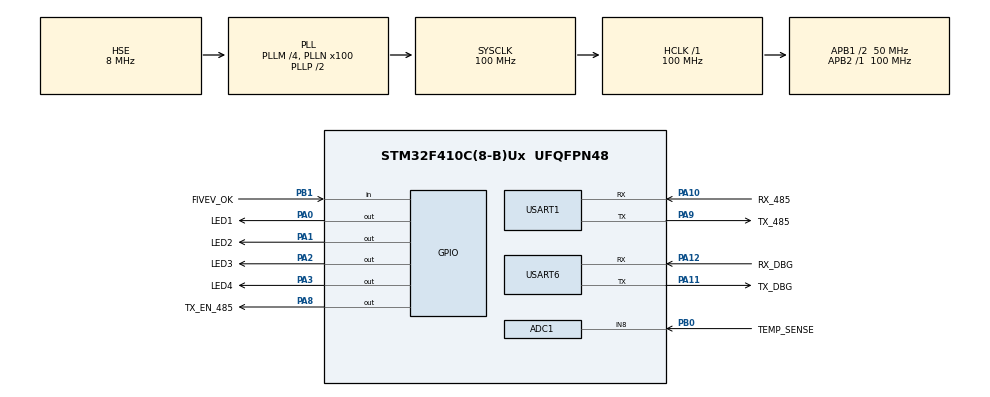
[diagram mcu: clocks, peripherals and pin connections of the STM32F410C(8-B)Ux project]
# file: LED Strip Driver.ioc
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ADC1.Channel-8\#ChannelRegularConversion=ADC_CHANNEL_8
ADC1.NbrOfConversionFlag=1
ADC1.Rank-8\#ChannelRegularConversion=1
ADC1.SamplingTime-8\#ChannelRegularConversion=ADC_SAMPLETIME_3CYCLES
ADC1.master=1
Mcu.Family=STM32F4
Mcu.Name=STM32F410C(8-B)Ux
Mcu.Package=UFQFPN48
NVIC.PriorityGroup=NVIC_PRIORITYGROUP_4
PA0-WKUP.GPIO_Label=LED1
PA0-WKUP.Signal=GPIO_Output
PA1.GPIO_Label=LED2
PA1.Signal=GPIO_Output
PA10.GPIO_Label=RX_485
PA10.Mode=Asynchronous
PA10.Signal=USART1_RX
PA11.GPIO_Label=TX_DBG
PA11.Mode=Asynchronous
PA11.Signal=USART6_TX
PA12.GPIO_Label=RX_DBG
PA12.Mode=Asynchronous
PA12.Signal=USART6_RX
PA13.Mode=Trace_Asynchronous_SW
PA13.Signal=SYS_JTMS-SWDIO
PA14.Mode=Trace_Asynchronous_SW
PA14.Signal=SYS_JTCK-SWCLK
PA2.GPIO_Label=LED3
PA2.Signal=GPIO_Output
PA3.GPIO_Label=LED4
PA3.Signal=GPIO_Output
PA8.GPIO_Label=TX_EN_485
PA8.Signal=GPIO_Output
PA9.GPIO_Label=TX_485
PA9.Mode=Asynchronous
PA9.Signal=USART1_TX
PB0.GPIO_Label=TEMP_SENSE
PB0.Signal=ADCx_IN8
PB1.GPIO_Label=FIVEV_OK
PB1.Signal=GPIO_Input
PB3.Mode=Trace_Asynchronous_SW
PB3.Signal=SYS_JTDO-SWO
PH0\ -\ OSC_IN.Mode=HSE-External-Oscillator
PH0\ -\ OSC_IN.Signal=RCC_OSC_IN
PH1\ -\ OSC_OUT.Mode=HSE-External-Oscillator
PH1\ -\ OSC_OUT.Signal=RCC_OSC_OUT
ProjectManager.HeapSize=0x800
ProjectManager.StackSize=0x800
ProjectManager.TargetToolchain=TrueSTUDIO
RCC.48MHZClocksFreq_Value=50000000
RCC.AHBFreq_Value=100000000
RCC.APB1CLKDivider=RCC_HCLK_DIV2
RCC.APB1Freq_Value=50000000
RCC.APB1TimFreq_Value=100000000
RCC.APB2Freq_Value=100000000
RCC.APB2TimFreq_Value=100000000
RCC.CortexFreq_Value=100000000
RCC.HCLKFreq_Value=100000000
RCC.HSE_VALUE=8000000
RCC.HSI_VALUE=16000000
RCC.LSE_VALUE=32768
RCC.PLLM=4
RCC.PLLN=100
RCC.PLLSourceVirtual=RCC_PLLSOURCE_HSE
RCC.SYSCLKFreq_VALUE=100000000
RCC.SYSCLKSource=RCC_SYSCLKSOURCE_PLLCLK
RCC.VCOOutputFreq_Value=200000000
SH.ADCx_IN8.0=ADC1_IN8,IN8
USART1.VirtualMode=VM_ASYNC
USART6.VirtualMode=VM_ASYNC
VP_TIM1_VS_ClockSourceINT.Mode=Internal
board=LED Strip Driver

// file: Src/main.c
/**
  ******************************************************************************
  * @file           : main.c
  * @brief          : Main program body
  ******************************************************************************
  ** This notice applies to any and all portions of this file
  * that are not between comment pairs USER CODE BEGIN and
  * USER CODE END. Other portions of this file, whether
  * inserted by the user or by software development tools
  * are owned by their respective copyright owners.
  *
  * COPYRIGHT(c) 2018 STMicroelectronics
  *
  * Redistribution and use in source and binary forms, with or without modification,
  * are permitted provided that the following conditions are met:
  *   1. Redistributions of source code must retain the above copyright notice,
  *      this list of conditions and the following disclaimer.
  *   2. Redistributions in binary form must reproduce the above copyright notice,
  *      this list of conditions and the following disclaimer in the documentation
  *      and/or other materials provided with the distribution.
  *   3. Neither the name of STMicroelectronics nor the names of its contributors
  *      may be used to endorse or promote products derived from this software
  *      without specific prior written permission.
  *
  * THIS SOFTWARE IS PROVIDED BY THE COPYRIGHT HOLDERS AND CONTRIBUTORS "AS IS"
  * AND ANY EXPRESS OR IMPLIED WARRANTIES, INCLUDING, BUT NOT LIMITED TO, THE
  * IMPLIED WARRANTIES OF MERCHANTABILITY AND FITNESS FOR A PARTICULAR PURPOSE ARE
  * DISCLAIMED. IN NO EVENT SHALL THE COPYRIGHT HOLDER OR CONTRIBUTORS BE LIABLE
  * FOR ANY DIRECT, INDIRECT, INCIDENTAL, SPECIAL, EXEMPLARY, OR CONSEQUENTIAL
  * DAMAGES (INCLUDING, BUT NOT LIMITED TO, PROCUREMENT OF SUBSTITUTE GOODS OR
  * SERVICES; LOSS OF USE, DATA, OR PROFITS; OR BUSINESS INTERRUPTION) HOWEVER
  * CAUSED AND ON ANY THEORY OF LIABILITY, WHETHER IN CONTRACT, STRICT LIABILITY,
  * OR TORT (INCLUDING NEGLIGENCE OR OTHERWISE) ARISING IN ANY WAY OUT OF THE USE
  * OF THIS SOFTWARE, EVEN IF ADVISED OF THE POSSIBILITY OF SUCH DAMAGE.
  *
  ******************************************************************************
  */
#include "main.h"
#include "stm32f4xx_hal.h"

/* USER CODE BEGIN Includes */
#include "user_main.h"

/* USER CODE END Includes */

ADC_HandleTypeDef hadc1;

TIM_HandleTypeDef htim1;

UART_HandleTypeDef huart1;
UART_HandleTypeDef huart6;

/* USER CODE BEGIN PV */
/* Private variables ---------------------------------------------------------*/

/* USER CODE END PV */

void SystemClock_Config(void);
static void MX_GPIO_Init(void);
static void MX_ADC1_Init(void);
static void MX_USART1_UART_Init(void);
static void MX_USART6_UART_Init(void);
static void MX_TIM1_Init(void);

/* USER CODE BEGIN PFP */
/* Private function prototypes -----------------------------------------------*/

/* USER CODE END PFP */

int main(void)
{

  /* MCU Configuration----------------------------------------------------------*/

  /* Reset of all peripherals, Initializes the Flash interface and the Systick. */
  HAL_Init();

  /* Configure the system clock */
  SystemClock_Config();

  /* Initialize all configured peripherals */
  MX_GPIO_Init();
  MX_ADC1_Init();
  MX_USART1_UART_Init();
  MX_USART6_UART_Init();
  MX_TIM1_Init();
  /* USER CODE BEGIN 2 */

  visInit();

  /* USER CODE END 2 */

  /* Infinite loop */
  /* USER CODE BEGIN WHILE */
  while (1)
  {
	  user_main();

  /* USER CODE END WHILE */

  }

}

void SystemClock_Config(void)
{

  RCC_OscInitTypeDef RCC_OscInitStruct;
  RCC_ClkInitTypeDef RCC_ClkInitStruct;

    /**Configure the main internal regulator output voltage
    */
  __HAL_RCC_PWR_CLK_ENABLE();

  __HAL_PWR_VOLTAGESCALING_CONFIG(PWR_REGULATOR_VOLTAGE_SCALE1);

    /**Initializes the CPU, AHB and APB busses clocks
    */
  RCC_OscInitStruct.OscillatorType = RCC_OSCILLATORTYPE_HSE;
  RCC_OscInitStruct.HSEState = RCC_HSE_ON;
  RCC_OscInitStruct.PLL.PLLState = RCC_PLL_ON;
  RCC_OscInitStruct.PLL.PLLSource = RCC_PLLSOURCE_HSE;
  RCC_OscInitStruct.PLL.PLLM = 4;
  RCC_OscInitStruct.PLL.PLLN = 100;
  RCC_OscInitStruct.PLL.PLLP = RCC_PLLP_DIV2;
  RCC_OscInitStruct.PLL.PLLQ = 4;
  RCC_OscInitStruct.PLL.PLLR = 2;
  if (HAL_RCC_OscConfig(&RCC_OscInitStruct) != HAL_OK)
  {
    _Error_Handler(__FILE__, __LINE__);
  }

    /**Initializes the CPU, AHB and APB busses clocks
    */
  RCC_ClkInitStruct.ClockType = RCC_CLOCKTYPE_HCLK|RCC_CLOCKTYPE_SYSCLK
                              |RCC_CLOCKTYPE_PCLK1|RCC_CLOCKTYPE_PCLK2;
  RCC_ClkInitStruct.SYSCLKSource = RCC_SYSCLKSOURCE_PLLCLK;
  RCC_ClkInitStruct.AHBCLKDivider = RCC_SYSCLK_DIV1;
  RCC_ClkInitStruct.APB1CLKDivider = RCC_HCLK_DIV2;
  RCC_ClkInitStruct.APB2CLKDivider = RCC_HCLK_DIV1;

  if (HAL_RCC_ClockConfig(&RCC_ClkInitStruct, FLASH_LATENCY_3) != HAL_OK)
  {
    _Error_Handler(__FILE__, __LINE__);
  }

    /**Configure the Systick interrupt time
    */
  HAL_SYSTICK_Config(HAL_RCC_GetHCLKFreq()/1000);

    /**Configure the Systick
    */
  HAL_SYSTICK_CLKSourceConfig(SYSTICK_CLKSOURCE_HCLK);

  /* SysTick_IRQn interrupt configuration */
  HAL_NVIC_SetPriority(SysTick_IRQn, 0, 0);
}

/* ADC1 init function */
static void MX_ADC1_Init(void)
{

  ADC_ChannelConfTypeDef sConfig;

    /**Configure the global features of the ADC (Clock, Resolution, Data Alignment and number of conversion)
    */
  hadc1.Instance = ADC1;
  hadc1.Init.ClockPrescaler = ADC_CLOCK_SYNC_PCLK_DIV4;
  hadc1.Init.Resolution = ADC_RESOLUTION_12B;
  hadc1.Init.ScanConvMode = DISABLE;
  hadc1.Init.ContinuousConvMode = DISABLE;
  hadc1.Init.DiscontinuousConvMode = DISABLE;
  hadc1.Init.ExternalTrigConvEdge = ADC_EXTERNALTRIGCONVEDGE_NONE;
  hadc1.Init.ExternalTrigConv = ADC_SOFTWARE_START;
  hadc1.Init.DataAlign = ADC_DATAALIGN_RIGHT;
  hadc1.Init.NbrOfConversion = 1;
  hadc1.Init.DMAContinuousRequests = DISABLE;
  hadc1.Init.EOCSelection = ADC_EOC_SINGLE_CONV;
  if (HAL_ADC_Init(&hadc1) != HAL_OK)
  {
    _Error_Handler(__FILE__, __LINE__);
  }

    /**Configure for the selected ADC regular channel its corresponding rank in the sequencer and its sample time.
    */
  sConfig.Channel = ADC_CHANNEL_8;
  sConfig.Rank = 1;
  sConfig.SamplingTime = ADC_SAMPLETIME_3CYCLES;
  if (HAL_ADC_ConfigChannel(&hadc1, &sConfig) != HAL_OK)
  {
    _Error_Handler(__FILE__, __LINE__);
  }

}

/* TIM1 init function */
static void MX_TIM1_Init(void)
{

  TIM_ClockConfigTypeDef sClockSourceConfig;
  TIM_MasterConfigTypeDef sMasterConfig;

  htim1.Instance = TIM1;
  htim1.Init.Prescaler = 0;
  htim1.Init.CounterMode = TIM_COUNTERMODE_UP;
  htim1.Init.Period = 0;
  htim1.Init.ClockDivision = TIM_CLOCKDIVISION_DIV1;
  htim1.Init.RepetitionCounter = 0;
  if (HAL_TIM_Base_Init(&htim1) != HAL_OK)
  {
    _Error_Handler(__FILE__, __LINE__);
  }

  sClockSourceConfig.ClockSource = TIM_CLOCKSOURCE_INTERNAL;
  if (HAL_TIM_ConfigClockSource(&htim1, &sClockSourceConfig) != HAL_OK)
  {
    _Error_Handler(__FILE__, __LINE__);
  }

  sMasterConfig.MasterOutputTrigger = TIM_TRGO_RESET;
  sMasterConfig.MasterSlaveMode = TIM_MASTERSLAVEMODE_DISABLE;
  if (HAL_TIMEx_MasterConfigSynchronization(&htim1, &sMasterConfig) != HAL_OK)
  {
    _Error_Handler(__FILE__, __LINE__);
  }

}

/* USART1 init function */
static void MX_USART1_UART_Init(void)
{

  huart1.Instance = USART1;
  huart1.Init.BaudRate = 115200;
  huart1.Init.WordLength = UART_WORDLENGTH_8B;
  huart1.Init.StopBits = UART_STOPBITS_1;
  huart1.Init.Parity = UART_PARITY_NONE;
  huart1.Init.Mode = UART_MODE_TX_RX;
  huart1.Init.HwFlowCtl = UART_HWCONTROL_NONE;
  huart1.Init.OverSampling = UART_OVERSAMPLING_16;
  if (HAL_UART_Init(&huart1) != HAL_OK)
  {
    _Error_Handler(__FILE__, __LINE__);
  }

}

/* USART6 init function */
static void MX_USART6_UART_Init(void)
{

  huart6.Instance = USART6;
  huart6.Init.BaudRate = 115200;
  huart6.Init.WordLength = UART_WORDLENGTH_8B;
  huart6.Init.StopBits = UART_STOPBITS_1;
  huart6.Init.Parity = UART_PARITY_NONE;
  huart6.Init.Mode = UART_MODE_TX_RX;
  huart6.Init.HwFlowCtl = UART_HWCONTROL_NONE;
  huart6.Init.OverSampling = UART_OVERSAMPLING_16;
  if (HAL_UART_Init(&huart6) != HAL_OK)
  {
    _Error_Handler(__FILE__, __LINE__);
  }

}

/** Configure pins as
        * Analog
        * Input
        * Output
        * EVENT_OUT
        * EXTI
*/
static void MX_GPIO_Init(void)
{

  GPIO_InitTypeDef GPIO_InitStruct;

  /* GPIO Ports Clock Enable */
  __HAL_RCC_GPIOH_CLK_ENABLE();
  __HAL_RCC_GPIOA_CLK_ENABLE();
  __HAL_RCC_GPIOB_CLK_ENABLE();

  /*Configure GPIO pin Output Level */
  HAL_GPIO_WritePin(GPIOA, LED1_Pin|LED2_Pin|LED3_Pin|LED4_Pin
                          |TX_EN_485_Pin, GPIO_PIN_RESET);

  /*Configure GPIO pins : LED1_Pin LED2_Pin LED3_Pin LED4_Pin
                           TX_EN_485_Pin */
  GPIO_InitStruct.Pin = LED1_Pin|LED2_Pin|LED3_Pin|LED4_Pin
                          |TX_EN_485_Pin;
  GPIO_InitStruct.Mode = GPIO_MODE_OUTPUT_PP;
  GPIO_InitStruct.Pull = GPIO_NOPULL;
  GPIO_InitStruct.Speed = GPIO_SPEED_FREQ_LOW;
  HAL_GPIO_Init(GPIOA, &GPIO_InitStruct);

  /*Configure GPIO pin : FIVEV_OK_Pin */
  GPIO_InitStruct.Pin = FIVEV_OK_Pin;
  GPIO_InitStruct.Mode = GPIO_MODE_INPUT;
  GPIO_InitStruct.Pull = GPIO_NOPULL;
  HAL_GPIO_Init(FIVEV_OK_GPIO_Port, &GPIO_InitStruct);

}

void _Error_Handler(char *file, int line)
{
  while(1)
  {
  }
}

/************************ (C) COPYRIGHT STMicroelectronics *****END OF FILE****/
